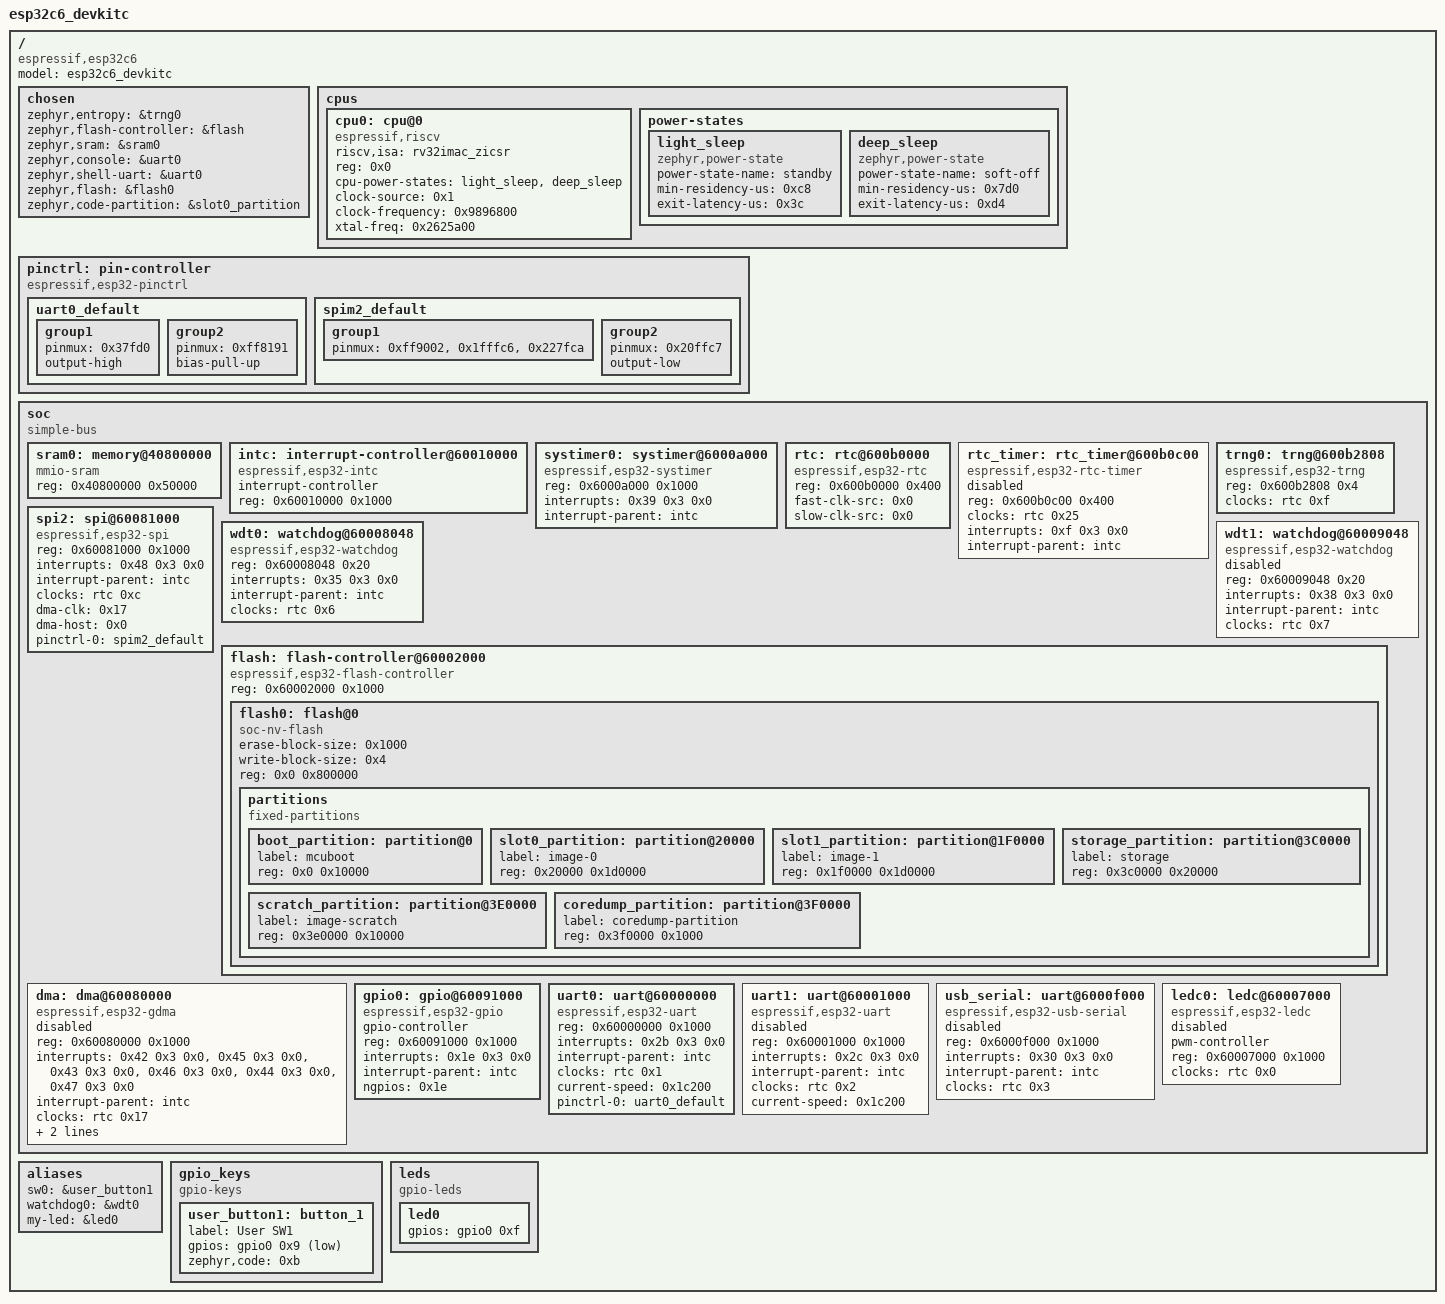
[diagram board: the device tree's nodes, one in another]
/dts-v1/;

/ {
	#address-cells = < 0x1 >;
	#size-cells = < 0x1 >;
	model = "esp32c6_devkitc";
	compatible = "espressif,esp32c6";
	chosen {
		zephyr,entropy = &trng0;
		zephyr,flash-controller = &flash;
		zephyr,sram = &sram0;
		zephyr,console = &uart0;
		zephyr,shell-uart = &uart0;
		zephyr,flash = &flash0;
		zephyr,code-partition = &slot0_partition;
	};
	cpus {
		#address-cells = < 0x1 >;
		#size-cells = < 0x0 >;
		cpu0: cpu@0 {
			device_type = "cpu";
			compatible = "espressif,riscv";
			riscv,isa = "rv32imac_zicsr";
			reg = < 0x0 >;
			cpu-power-states = < &light_sleep &deep_sleep >;
			clock-source = < 0x1 >;
			clock-frequency = < 0x9896800 >;
			xtal-freq = < 0x2625a00 >;
		};
		power-states {
			light_sleep: light_sleep {
				compatible = "zephyr,power-state";
				power-state-name = "standby";
				min-residency-us = < 0xc8 >;
				exit-latency-us = < 0x3c >;
				phandle = < 0x1 >;
			};
			deep_sleep: deep_sleep {
				compatible = "zephyr,power-state";
				power-state-name = "soft-off";
				min-residency-us = < 0x7d0 >;
				exit-latency-us = < 0xd4 >;
				phandle = < 0x2 >;
			};
		};
	};
	pinctrl: pin-controller {
		compatible = "espressif,esp32-pinctrl";
		status = "okay";
		uart0_default: uart0_default {
			phandle = < 0x6 >;
			group1 {
				pinmux = < 0x37fd0 >;
				output-high;
			};
			group2 {
				pinmux = < 0xff8191 >;
				bias-pull-up;
			};
		};
		spim2_default: spim2_default {
			phandle = < 0x5 >;
			group1 {
				pinmux = < 0xff9002 >, < 0x1fffc6 >, < 0x227fca >;
			};
			group2 {
				pinmux = < 0x20ffc7 >;
				output-low;
			};
		};
	};
	soc {
		#address-cells = < 0x1 >;
		#size-cells = < 0x1 >;
		compatible = "simple-bus";
		ranges;
		sram0: memory@40800000 {
			compatible = "mmio-sram";
			reg = < 0x40800000 0x50000 >;
		};
		intc: interrupt-controller@60010000 {
			compatible = "espressif,esp32-intc";
			#address-cells = < 0x0 >;
			#interrupt-cells = < 0x3 >;
			interrupt-controller;
			reg = < 0x60010000 0x1000 >;
			status = "okay";
			phandle = < 0x3 >;
		};
		systimer0: systimer@6000a000 {
			compatible = "espressif,esp32-systimer";
			reg = < 0x6000a000 0x1000 >;
			interrupts = < 0x39 0x3 0x0 >;
			interrupt-parent = < &intc >;
			status = "okay";
		};
		rtc: rtc@600b0000 {
			compatible = "espressif,esp32-rtc";
			reg = < 0x600b0000 0x400 >;
			fast-clk-src = < 0x0 >;
			slow-clk-src = < 0x0 >;
			#clock-cells = < 0x1 >;
			status = "okay";
			phandle = < 0x4 >;
		};
		rtc_timer: rtc_timer@600b0c00 {
			compatible = "espressif,esp32-rtc-timer";
			reg = < 0x600b0c00 0x400 >;
			clocks = < &rtc 0x25 >;
			interrupts = < 0xf 0x3 0x0 >;
			interrupt-parent = < &intc >;
			status = "disabled";
		};
		trng0: trng@600b2808 {
			compatible = "espressif,esp32-trng";
			reg = < 0x600b2808 0x4 >;
			clocks = < &rtc 0xf >;
			status = "okay";
		};
		spi2: spi@60081000 {
			compatible = "espressif,esp32-spi";
			reg = < 0x60081000 0x1000 >;
			interrupts = < 0x48 0x3 0x0 >;
			interrupt-parent = < &intc >;
			clocks = < &rtc 0xc >;
			dma-clk = < 0x17 >;
			dma-host = < 0x0 >;
			status = "okay";
			#address-cells = < 0x1 >;
			#size-cells = < 0x0 >;
			pinctrl-0 = < &spim2_default >;
			pinctrl-names = "default";
		};
		wdt0: watchdog@60008048 {
			compatible = "espressif,esp32-watchdog";
			reg = < 0x60008048 0x20 >;
			interrupts = < 0x35 0x3 0x0 >;
			interrupt-parent = < &intc >;
			clocks = < &rtc 0x6 >;
			status = "okay";
		};
		wdt1: watchdog@60009048 {
			compatible = "espressif,esp32-watchdog";
			reg = < 0x60009048 0x20 >;
			interrupts = < 0x38 0x3 0x0 >;
			interrupt-parent = < &intc >;
			clocks = < &rtc 0x7 >;
			status = "disabled";
		};
		flash: flash-controller@60002000 {
			compatible = "espressif,esp32-flash-controller";
			reg = < 0x60002000 0x1000 >;
			#address-cells = < 0x1 >;
			#size-cells = < 0x1 >;
			flash0: flash@0 {
				compatible = "soc-nv-flash";
				erase-block-size = < 0x1000 >;
				write-block-size = < 0x4 >;
				reg = < 0x0 0x800000 >;
				partitions {
					compatible = "fixed-partitions";
					#address-cells = < 0x1 >;
					#size-cells = < 0x1 >;
					boot_partition: partition@0 {
						label = "mcuboot";
						reg = < 0x0 0x10000 >;
					};
					slot0_partition: partition@20000 {
						label = "image-0";
						reg = < 0x20000 0x1d0000 >;
					};
					slot1_partition: partition@1F0000 {
						label = "image-1";
						reg = < 0x1f0000 0x1d0000 >;
					};
					storage_partition: partition@3C0000 {
						label = "storage";
						reg = < 0x3c0000 0x20000 >;
					};
					scratch_partition: partition@3E0000 {
						label = "image-scratch";
						reg = < 0x3e0000 0x10000 >;
					};
					coredump_partition: partition@3F0000 {
						label = "coredump-partition";
						reg = < 0x3f0000 0x1000 >;
					};
				};
			};
		};
		dma: dma@60080000 {
			compatible = "espressif,esp32-gdma";
			reg = < 0x60080000 0x1000 >;
			#dma-cells = < 0x1 >;
			interrupts = < 0x42 0x3 0x0 >, < 0x45 0x3 0x0 >, < 0x43 0x3 0x0 >, < 0x46 0x3 0x0 >, < 0x44 0x3 0x0 >, < 0x47 0x3 0x0 >;
			interrupt-parent = < &intc >;
			clocks = < &rtc 0x17 >;
			dma-channels = < 0x6 >;
			dma-buf-addr-alignment = < 0x4 >;
			status = "disabled";
		};
		gpio0: gpio@60091000 {
			compatible = "espressif,esp32-gpio";
			gpio-controller;
			#gpio-cells = < 0x2 >;
			reg = < 0x60091000 0x1000 >;
			interrupts = < 0x1e 0x3 0x0 >;
			interrupt-parent = < &intc >;
			ngpios = < 0x1e >;
			status = "okay";
			phandle = < 0x7 >;
		};
		uart0: uart@60000000 {
			compatible = "espressif,esp32-uart";
			reg = < 0x60000000 0x1000 >;
			status = "okay";
			interrupts = < 0x2b 0x3 0x0 >;
			interrupt-parent = < &intc >;
			clocks = < &rtc 0x1 >;
			current-speed = < 0x1c200 >;
			pinctrl-0 = < &uart0_default >;
			pinctrl-names = "default";
		};
		uart1: uart@60001000 {
			compatible = "espressif,esp32-uart";
			reg = < 0x60001000 0x1000 >;
			status = "disabled";
			interrupts = < 0x2c 0x3 0x0 >;
			interrupt-parent = < &intc >;
			clocks = < &rtc 0x2 >;
			current-speed = < 0x1c200 >;
		};
		usb_serial: uart@6000f000 {
			compatible = "espressif,esp32-usb-serial";
			reg = < 0x6000f000 0x1000 >;
			status = "disabled";
			interrupts = < 0x30 0x3 0x0 >;
			interrupt-parent = < &intc >;
			clocks = < &rtc 0x3 >;
		};
		ledc0: ledc@60007000 {
			compatible = "espressif,esp32-ledc";
			pwm-controller;
			#pwm-cells = < 0x3 >;
			reg = < 0x60007000 0x1000 >;
			clocks = < &rtc 0x0 >;
			status = "disabled";
		};
	};
	aliases {
		sw0 = &user_button1;
		watchdog0 = &wdt0;
		my-led = &led0;
	};
	gpio_keys {
		compatible = "gpio-keys";
		user_button1: button_1 {
			label = "User SW1";
			gpios = < &gpio0 0x9 0x11 >;
			zephyr,code = < 0xb >;
		};
	};
	leds {
		compatible = "gpio-leds";
		led0: led0 {
			gpios = < &gpio0 0xf 0x0 >;
		};
	};
};
